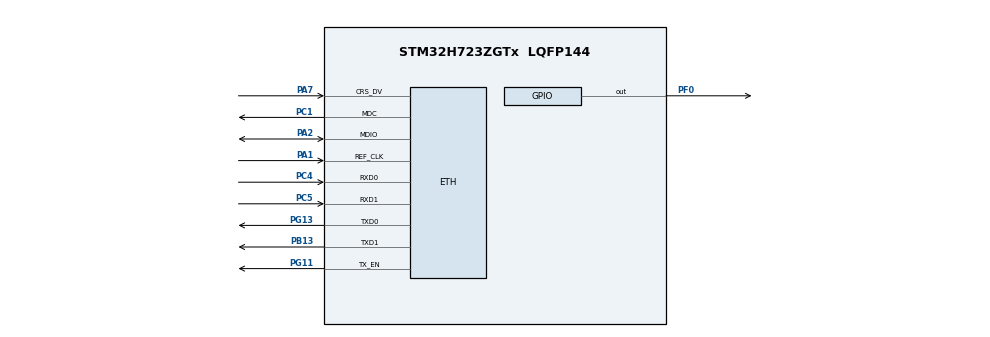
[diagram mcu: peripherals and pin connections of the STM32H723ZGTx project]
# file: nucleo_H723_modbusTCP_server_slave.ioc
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CORTEX_M7.AccessPermission-Cortex_Memory_Protection_Unit_Region1_Settings=MPU_REGION_FULL_ACCESS
CORTEX_M7.AccessPermission-Cortex_Memory_Protection_Unit_Region2_Settings=MPU_REGION_FULL_ACCESS
CORTEX_M7.BaseAddress-Cortex_Memory_Protection_Unit_Region1_Settings=0x30000000
CORTEX_M7.BaseAddress-Cortex_Memory_Protection_Unit_Region2_Settings=0x30004000
CORTEX_M7.CPU_DCache=Enabled
CORTEX_M7.CPU_ICache=Enabled
CORTEX_M7.DisableExec-Cortex_Memory_Protection_Unit_Region0_Settings=MPU_INSTRUCTION_ACCESS_DISABLE
CORTEX_M7.Enable-Cortex_Memory_Protection_Unit_Region0_Settings=MPU_REGION_ENABLE
CORTEX_M7.Enable-Cortex_Memory_Protection_Unit_Region1_Settings=MPU_REGION_ENABLE
CORTEX_M7.Enable-Cortex_Memory_Protection_Unit_Region2_Settings=MPU_REGION_ENABLE
CORTEX_M7.IsBufferable-Cortex_Memory_Protection_Unit_Region1_Settings=MPU_ACCESS_BUFFERABLE
CORTEX_M7.IsShareable-Cortex_Memory_Protection_Unit_Region0_Settings=MPU_ACCESS_SHAREABLE
CORTEX_M7.IsShareable-Cortex_Memory_Protection_Unit_Region2_Settings=MPU_ACCESS_SHAREABLE
CORTEX_M7.MPU_Control=MPU_PRIVILEGED_DEFAULT
CORTEX_M7.Size-Cortex_Memory_Protection_Unit_Region0_Settings=MPU_REGION_SIZE_4GB
CORTEX_M7.Size-Cortex_Memory_Protection_Unit_Region1_Settings=MPU_REGION_SIZE_256B
CORTEX_M7.Size-Cortex_Memory_Protection_Unit_Region2_Settings=MPU_REGION_SIZE_16KB
CORTEX_M7.SubRegionDisable-Cortex_Memory_Protection_Unit_Region0_Settings=0x87
CORTEX_M7.TypeExtField-Cortex_Memory_Protection_Unit_Region2_Settings=MPU_TEX_LEVEL1
ETH.MediaInterface=HAL_ETH_RMII_MODE
ETH.RxBuffLen=1536
FREERTOS.Tasks01=defaultTask,24,128,StartDefaultTask,Default,NULL,Dynamic,NULL,NULL
FREERTOS.configQUEUE_REGISTRY_SIZE=12
FREERTOS.configUSE_NEWLIB_REENTRANT=1
LWIP.BSP.number=1
LWIP.CMSIS_VERSION-Enabled=1
LWIP.GATEWAY_ADDRESS=192.168.001.001
LWIP.IP_ADDRESS=192.168.001.151
LWIP.LWIP_DHCP=0
LWIP.MEM_SIZE=10*1024
LWIP.NETMASK_ADDRESS=255.255.255.000
LWIP.Version=v2.1.2_Cube
LWIP0.BSP.STBoard=false
LWIP0.BSP.api=BSP_COMPONENT_DRIVER
LWIP0.BSP.component=LAN8742
LWIP0.BSP.instance=LAN8742
LWIP0.BSP.name=Driver_PHY
LWIP0.BSP.semaphore=S_LAN8742
LWIP0.BSP.solution=LAN8742
Mcu.Family=STM32H7
Mcu.Name=STM32H723ZGTx
Mcu.Package=LQFP144
NVIC.ETH_IRQn=true\:15\:0\:true\:false\:true\:true\:true\:true\:true
NVIC.PriorityGroup=NVIC_PRIORITYGROUP_4
NVIC.TIM6_DAC_IRQn=true\:15\:0\:false\:false\:true\:false\:false\:true\:true
NVIC.TimeBase=TIM6_DAC_IRQn
NVIC.TimeBaseIP=TIM6
PA1.GPIO_Speed=GPIO_SPEED_FREQ_VERY_HIGH
PA1.Mode=RMII
PA1.Signal=ETH_REF_CLK
PA2.GPIO_Speed=GPIO_SPEED_FREQ_VERY_HIGH
PA2.Mode=RMII
PA2.Signal=ETH_MDIO
PA7.GPIO_Speed=GPIO_SPEED_FREQ_VERY_HIGH
PA7.Mode=RMII
PA7.Signal=ETH_CRS_DV
PB13.GPIO_Speed=GPIO_SPEED_FREQ_VERY_HIGH
PB13.Mode=RMII
PB13.Signal=ETH_TXD1
PC1.GPIO_Speed=GPIO_SPEED_FREQ_VERY_HIGH
PC1.Mode=RMII
PC1.Signal=ETH_MDC
PC4.GPIO_Speed=GPIO_SPEED_FREQ_VERY_HIGH
PC4.Mode=RMII
PC4.Signal=ETH_RXD0
PC5.GPIO_Speed=GPIO_SPEED_FREQ_VERY_HIGH
PC5.Mode=RMII
PC5.Signal=ETH_RXD1
PF0.Signal=GPIO_Output
PG11.GPIO_Speed=GPIO_SPEED_FREQ_VERY_HIGH
PG11.Mode=RMII
PG11.Signal=ETH_TX_EN
PG13.GPIO_Speed=GPIO_SPEED_FREQ_VERY_HIGH
PG13.Mode=RMII
PG13.Signal=ETH_TXD0
PH0-OSC_IN.Mode=HSE-External-Oscillator
PH0-OSC_IN.Signal=RCC_OSC_IN
PH1-OSC_OUT.Mode=HSE-External-Oscillator
PH1-OSC_OUT.Signal=RCC_OSC_OUT
ProjectManager.HeapSize=0x200
ProjectManager.StackSize=0x400
ProjectManager.TargetToolchain=STM32CubeIDE
RCC.ADCFreq_Value=129000000
RCC.APB1Freq_Value=137500000
RCC.APB2Freq_Value=137500000
RCC.APB3Freq_Value=137500000
RCC.APB4Freq_Value=137500000
RCC.CortexFreq_Value=550000000
RCC.D1PPRE=RCC_APB3_DIV2
RCC.D2PPRE1=RCC_APB1_DIV2
RCC.D2PPRE2=RCC_APB2_DIV2
RCC.D3PPRE=RCC_APB4_DIV2
RCC.DIVM1=4
RCC.DIVN1=34
RCC.DIVP1=1
RCC.HCLKFreq_Value=275000000
RCC.HPRE=RCC_HCLK_DIV2
RCC.PLL2FRACN=0
RCC.PLL3FRACN=0
RCC.PLLFRACN=3072
RCC.SYSCLKFreq_VALUE=550000000
RCC.SYSCLKSource=RCC_SYSCLKSOURCE_PLLCLK
RCC.USBFreq_Value=275000000
VP_FREERTOS_VS_CMSIS_V2.Mode=CMSIS_V2
VP_LWIP_VS_Enabled.Mode=Enabled
VP_MEMORYMAP_VS_MEMORYMAP.Mode=CurAppReg
VP_SYS_VS_tim6.Mode=TIM6
board=custom

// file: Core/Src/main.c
/* USER CODE BEGIN Header */
/**
  ******************************************************************************
  * @file           : main.c
  * @brief          : Main program body
  ******************************************************************************
  * @attention
  *
  * Copyright (c) 2025 STMicroelectronics.
  * All rights reserved.
  *
  * This software is licensed under terms that can be found in the LICENSE file
  * in the root directory of this software component.
  * If no LICENSE file comes with this software, it is provided AS-IS.
  *
  ******************************************************************************
  */
/* USER CODE END Header */
#include "main.h"
#include "cmsis_os.h"
#include "lwip.h"

/* USER CODE BEGIN Includes */
#include "tcpserver_modbus.h"
/* USER CODE END Includes */

/* Definitions for defaultTask */
osThreadId_t defaultTaskHandle;
const osThreadAttr_t defaultTask_attributes = {
  .name = "defaultTask",
  .stack_size = 128 * 4,
  .priority = (osPriority_t) osPriorityNormal,
};
/* USER CODE BEGIN PV */
modbus_t myModbus;
uint16_t ModbusData[40];
/* USER CODE END PV */

void SystemClock_Config(void);
static void MPU_Config(void);
static void MX_GPIO_Init(void);
void StartDefaultTask(void *argument);

int main(void)
{

  /* MPU Configuration--------------------------------------------------------*/
  MPU_Config();

  /* Enable the CPU Cache */

  /* Enable I-Cache---------------------------------------------------------*/
  SCB_EnableICache();

  /* Enable D-Cache---------------------------------------------------------*/
  SCB_EnableDCache();

  /* MCU Configuration--------------------------------------------------------*/

  /* Reset of all peripherals, Initializes the Flash interface and the Systick. */
  HAL_Init();

  /* Configure the system clock */
  SystemClock_Config();

  /* Initialize all configured peripherals */
  MX_GPIO_Init();
  /* USER CODE BEGIN 2 */
  myModbus.u16Port=502;//port Address
  myModbus.u8slaveID=0x01;//slave Address for modbus
  myModbus.u16reg=ModbusData;//buffer register
  myModbus.u16regsize= sizeof(ModbusData)/sizeof(ModbusData[0]);//get buffer size

  HAL_Delay(1000);//must used
  /* USER CODE END 2 */

  /* Init scheduler */
  osKernelInitialize();

  /* Create the thread(s) */
  /* creation of defaultTask */
  defaultTaskHandle = osThreadNew(StartDefaultTask, NULL, &defaultTask_attributes);

  /* Start scheduler */
  osKernelStart();

  /* We should never get here as control is now taken by the scheduler */

  /* Infinite loop */
  while (1)
  {

  }
}

void SystemClock_Config(void)
{
  RCC_OscInitTypeDef RCC_OscInitStruct = {0};
  RCC_ClkInitTypeDef RCC_ClkInitStruct = {0};

  /** Supply configuration update enable
  */
  HAL_PWREx_ConfigSupply(PWR_LDO_SUPPLY);

  /** Configure the main internal regulator output voltage
  */
  __HAL_PWR_VOLTAGESCALING_CONFIG(PWR_REGULATOR_VOLTAGE_SCALE0);

  while(!__HAL_PWR_GET_FLAG(PWR_FLAG_VOSRDY)) {}

  /** Initializes the RCC Oscillators according to the specified parameters
  * in the RCC_OscInitTypeDef structure.
  */
  RCC_OscInitStruct.OscillatorType = RCC_OSCILLATORTYPE_HSI;
  RCC_OscInitStruct.HSIState = RCC_HSI_DIV1;
  RCC_OscInitStruct.HSICalibrationValue = 64;
  RCC_OscInitStruct.PLL.PLLState = RCC_PLL_ON;
  RCC_OscInitStruct.PLL.PLLSource = RCC_PLLSOURCE_HSI;
  RCC_OscInitStruct.PLL.PLLM = 4;
  RCC_OscInitStruct.PLL.PLLN = 34;
  RCC_OscInitStruct.PLL.PLLP = 1;
  RCC_OscInitStruct.PLL.PLLQ = 2;
  RCC_OscInitStruct.PLL.PLLR = 2;
  RCC_OscInitStruct.PLL.PLLRGE = RCC_PLL1VCIRANGE_3;
  RCC_OscInitStruct.PLL.PLLVCOSEL = RCC_PLL1VCOWIDE;
  RCC_OscInitStruct.PLL.PLLFRACN = 3072;
  if (HAL_RCC_OscConfig(&RCC_OscInitStruct) != HAL_OK)
  {
    Error_Handler();
  }

  /** Initializes the CPU, AHB and APB buses clocks
  */
  RCC_ClkInitStruct.ClockType = RCC_CLOCKTYPE_HCLK|RCC_CLOCKTYPE_SYSCLK
                              |RCC_CLOCKTYPE_PCLK1|RCC_CLOCKTYPE_PCLK2
                              |RCC_CLOCKTYPE_D3PCLK1|RCC_CLOCKTYPE_D1PCLK1;
  RCC_ClkInitStruct.SYSCLKSource = RCC_SYSCLKSOURCE_PLLCLK;
  RCC_ClkInitStruct.SYSCLKDivider = RCC_SYSCLK_DIV1;
  RCC_ClkInitStruct.AHBCLKDivider = RCC_HCLK_DIV2;
  RCC_ClkInitStruct.APB3CLKDivider = RCC_APB3_DIV2;
  RCC_ClkInitStruct.APB1CLKDivider = RCC_APB1_DIV2;
  RCC_ClkInitStruct.APB2CLKDivider = RCC_APB2_DIV2;
  RCC_ClkInitStruct.APB4CLKDivider = RCC_APB4_DIV2;

  if (HAL_RCC_ClockConfig(&RCC_ClkInitStruct, FLASH_LATENCY_3) != HAL_OK)
  {
    Error_Handler();
  }
}

static void MX_GPIO_Init(void)
{
  GPIO_InitTypeDef GPIO_InitStruct = {0};

  /* GPIO Ports Clock Enable */
  __HAL_RCC_GPIOF_CLK_ENABLE();
  __HAL_RCC_GPIOH_CLK_ENABLE();
  __HAL_RCC_GPIOC_CLK_ENABLE();
  __HAL_RCC_GPIOA_CLK_ENABLE();
  __HAL_RCC_GPIOB_CLK_ENABLE();
  __HAL_RCC_GPIOG_CLK_ENABLE();

  /*Configure GPIO pin Output Level */
  HAL_GPIO_WritePin(GPIOF, GPIO_PIN_0, GPIO_PIN_RESET);

  /*Configure GPIO pin : PF0 */
  GPIO_InitStruct.Pin = GPIO_PIN_0;
  GPIO_InitStruct.Mode = GPIO_MODE_OUTPUT_PP;
  GPIO_InitStruct.Pull = GPIO_NOPULL;
  GPIO_InitStruct.Speed = GPIO_SPEED_FREQ_LOW;
  HAL_GPIO_Init(GPIOF, &GPIO_InitStruct);

}

void StartDefaultTask(void *argument)
{
  /* init code for LWIP */
  MX_LWIP_Init();
  /* USER CODE BEGIN 5 */
  tcpserver_init(&myModbus);
  /* Infinite loop */
  for(;;)
  {
    HAL_Delay(1);
  }
  /* USER CODE END 5 */
}

 /* MPU Configuration */

void MPU_Config(void)
{
  MPU_Region_InitTypeDef MPU_InitStruct = {0};

  /* Disables the MPU */
  HAL_MPU_Disable();

  /** Initializes and configures the Region and the memory to be protected
  */
  MPU_InitStruct.Enable = MPU_REGION_ENABLE;
  MPU_InitStruct.Number = MPU_REGION_NUMBER0;
  MPU_InitStruct.BaseAddress = 0x0;
  MPU_InitStruct.Size = MPU_REGION_SIZE_4GB;
  MPU_InitStruct.SubRegionDisable = 0x87;
  MPU_InitStruct.TypeExtField = MPU_TEX_LEVEL0;
  MPU_InitStruct.AccessPermission = MPU_REGION_NO_ACCESS;
  MPU_InitStruct.DisableExec = MPU_INSTRUCTION_ACCESS_DISABLE;
  MPU_InitStruct.IsShareable = MPU_ACCESS_SHAREABLE;
  MPU_InitStruct.IsCacheable = MPU_ACCESS_NOT_CACHEABLE;
  MPU_InitStruct.IsBufferable = MPU_ACCESS_NOT_BUFFERABLE;

  HAL_MPU_ConfigRegion(&MPU_InitStruct);

  /** Initializes and configures the Region and the memory to be protected
  */
  MPU_InitStruct.Number = MPU_REGION_NUMBER1;
  MPU_InitStruct.BaseAddress = 0x30000000;
  MPU_InitStruct.Size = MPU_REGION_SIZE_256B;
  MPU_InitStruct.SubRegionDisable = 0x0;
  MPU_InitStruct.AccessPermission = MPU_REGION_FULL_ACCESS;
  MPU_InitStruct.DisableExec = MPU_INSTRUCTION_ACCESS_ENABLE;
  MPU_InitStruct.IsShareable = MPU_ACCESS_NOT_SHAREABLE;
  MPU_InitStruct.IsBufferable = MPU_ACCESS_BUFFERABLE;

  HAL_MPU_ConfigRegion(&MPU_InitStruct);

  /** Initializes and configures the Region and the memory to be protected
  */
  MPU_InitStruct.Number = MPU_REGION_NUMBER2;
  MPU_InitStruct.BaseAddress = 0x30004000;
  MPU_InitStruct.Size = MPU_REGION_SIZE_16KB;
  MPU_InitStruct.TypeExtField = MPU_TEX_LEVEL1;
  MPU_InitStruct.IsShareable = MPU_ACCESS_SHAREABLE;
  MPU_InitStruct.IsBufferable = MPU_ACCESS_NOT_BUFFERABLE;

  HAL_MPU_ConfigRegion(&MPU_InitStruct);
  /* Enables the MPU */
  HAL_MPU_Enable(MPU_PRIVILEGED_DEFAULT);

}

void HAL_TIM_PeriodElapsedCallback(TIM_HandleTypeDef *htim)
{
  if (htim->Instance == TIM6) {
    HAL_IncTick();
  }
}

void Error_Handler(void)
{
  __disable_irq();
  while (1)
  {
  }
}
